# R9A09G057H register map
Vendor: Renesas Electronics; File version: 1.00
CPU: other r0p3, little endian, MPU, FPU, vendor SysTick, 4 interrupt priority bits, 480 interrupts
Registers are 32-bit, read-write, no defined reset value unless marked. A register's access mark holds for its fields unless they carry their own. Offsets are from the block's base; [hi:lo] are bit positions; {n}, {i} and the like mark numbered series.

## R_SPI_B0 — IO define file for spi.
Base 0x12800000
Same registers: R_SPI_B1 0x12800400, R_SPI_B2 0x12800800
0x00 SPDR
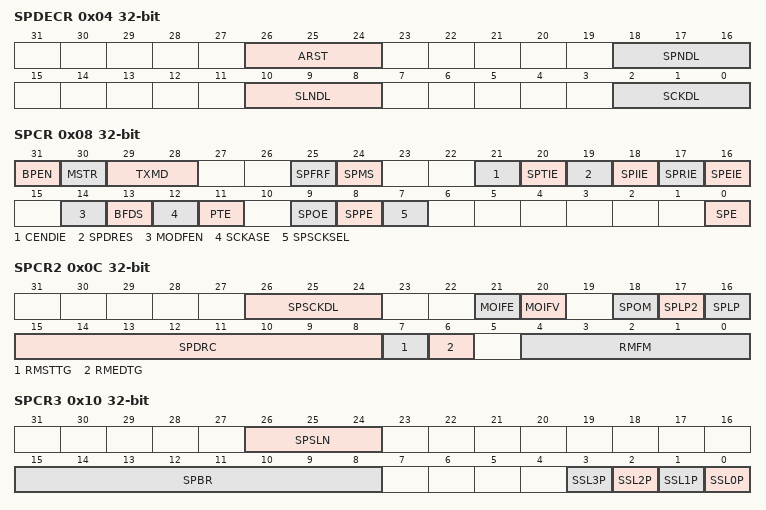
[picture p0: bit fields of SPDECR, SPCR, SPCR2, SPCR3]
0x04 SPDECR — RSPI Delay Control Register
  [26:24] ARST — Receive Sampling Timing Adjustment bits
  [18:16] SPNDL — RSPI Next-Access Delay
  [10:8] SLNDL — SSL Negation Delay
  [2:0] SCKDL — RSPCK Delay
0x08 SPCR — RSPI Control Register
  [31] BPEN — Synchronization Circuit Bypass Enable
  [30] MSTR — RSPI Master/Slave Mode Select
  [29:28] TXMD — Communication Mode Select
  [25] SPFRF — RSPI Frame Format Select
  [24] SPMS — RSPI Mode Select
  [21] CENDIE — RSPI Communication End Interrupt Enable
  [20] SPTIE — RSPI Transmit Buffer Empty Interrupt Enable
  [19] SPDRES — RSPI receive data ready error select
  [18] SPIIE — RSPI Idle Interrupt Enable
  [17] SPRIE — RSPI Receive Buffer Full Interrupt Enable
  [16] SPEIE — RSPI Error Interrupt Enable
  [14] MODFEN — Mode Fault Error Detection Enable
  [13] BFDS — Between Burst Transfer Frames Delay Select
  [12] SCKASE — RSPCK Auto-Stop Function Enable
  [11] PTE — Parity Self-Diagnosis Enable
  [9] SPOE — Parity Mode
  [8] SPPE — Parity Enable
  [7] SPSCKSEL — RSPI Master Receive Clock Select
  [0] SPE — RSPI Function Enable
0x0C SPCR2 — RSPI Control Register 2
  [26:24] SPSCKDL
  [21] MOIFE — MOSI Idle Fixed Value Enable
  [20] MOIFV — MOSI Idle Fixed Value
  [18] SPOM
  [17] SPLP2 — RSPI Loopback 2
  [16] SPLP — RSPI Loopback
  [15:8] SPDRC — RSPI received data ready detect adjustment
  [7] RMSTTG wo — Start Trigger in Master Receive only
  [6] RMEDTG wo — End Trigger in Master Receive only
  [4:0] RMFM — Frame processing count setting in Master Receive only
0x10 SPCR3 — RSPI Control Register 3
  [26:24] SPSLN — RSPI Sequence Length
  [15:8] SPBR — SPI Bit Rate
  [n] SSL{n}P (n=0..3) — SSL{n} Signal Polarity
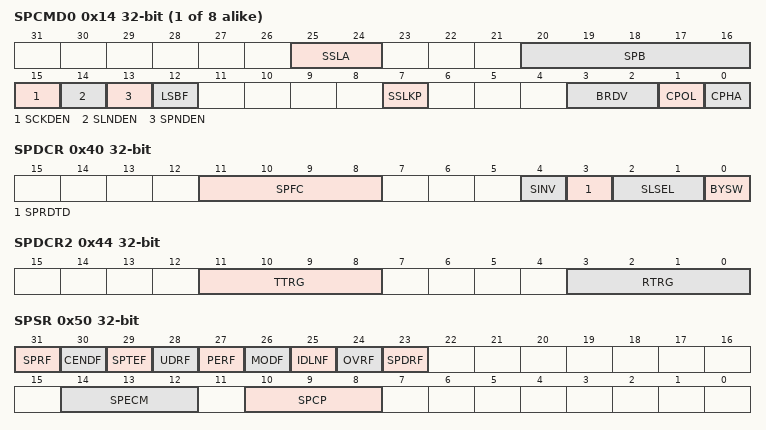
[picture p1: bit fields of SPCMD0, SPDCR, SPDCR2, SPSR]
{0x14+4i} SPCMD{i} (i=0..7) — RSPI Command Register
  [25:24] SSLA — SSL Signal Assertion
  [20:16] SPB — RSPI Data Length
  [15] SCKDEN — RSPCK Delay Setting Enable
  [14] SLNDEN — SSL Negation Delay Setting Enable
  [13] SPNDEN — RSPI Next-Access Delay Enable
  [12] LSBF — RSPI LSB First
  [7] SSLKP — SSL Signal Level Hold
  [3:2] BRDV — Bit Rate Division
  [1] CPOL — RSPCK Polarity
  [0] CPHA — RSPCK Phase
0x40 SPDCR — RSPI Data Control Register
  [11:8] SPFC — Frame Count
  [4] SINV — Serial data invert bit
  [3] SPRDTD — RSPI Receive Data or Transmit Data Select
  [2:1] SLSEL
  [0] BYSW — Byte Swap Operating Mode Select
0x44 SPDCR2 — RSPI Data Control Register 2
  [11:8] TTRG — Transmission FIFO threshold setting
  [3:0] RTRG — Receive FIFO threshold setting
0x50 SPSR ro — SPI Status Register
  [31] SPRF — RSPI Receive Buffer Full Flag
  [30] CENDF — Communication End Flag
  [29] SPTEF — RSPI Transmit Buffer Empty Flag
  [28] UDRF — Underrun Error Flag
  [27] PERF — Parity Error Flag
  [26] MODF — Mode Fault Error Flag
  [25] IDLNF — RSPI Idle Flag
  [24] OVRF — Overrun Error Flag
  [23] SPDRF — RSPI Receive Data Ready Flag
  [14:12] SPECM — RSPI Error Command
  [10:8] SPCP — RSPI Command Pointer
0x58 SPTFSR ro — RSPI Transfer FIFO Status Register
  [4:0] TFDN — Transmit FIFO data empty stage number
0x5C SPRFSR ro — RSPI Receive FIFO Status Register
  [4:0] RFDN — Receive FIFO data store stage number
0x60 SPPSR ro — RSPI Poling Register
  [0] SPEPS — RSPI Poling Status
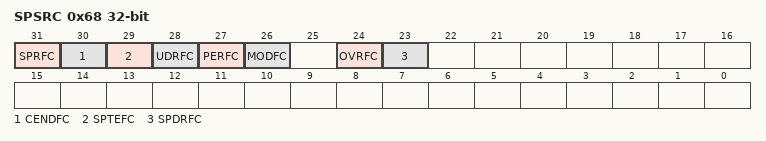
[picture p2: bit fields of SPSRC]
0x68 SPSRC — RSPI Status Clear Register
  [31] SPRFC wo — RSPI Receive Buffer Full Flag Clear
  [30] CENDFC wo — Communication End Flag Clear
  [29] SPTEFC wo — RSPI Transmit Buffer Empty Flag Clear
  [28] UDRFC wo — Underrun Error Flag Clear
  [27] PERFC wo — Parity Error Flag Clear
  [26] MODFC wo — Mode Fault Error Flag Clear
  [24] OVRFC wo — Overrun Error Flag Clear
  [23] SPDRFC wo — RSPI Receive Data Ready Flag Clear
0x6C SPFCR — RSPI FIFO Clear Register
  [0] SPFRST wo — RSPI FIFO clear
